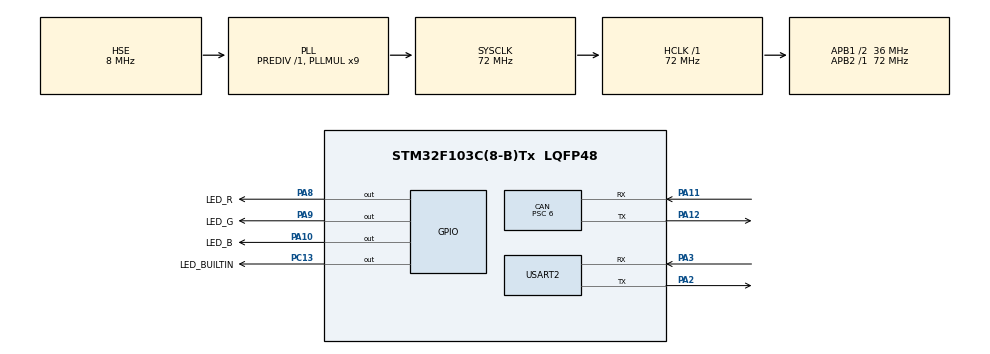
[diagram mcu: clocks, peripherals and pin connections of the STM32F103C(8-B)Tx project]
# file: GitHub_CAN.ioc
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CAN.ABOM=ENABLE
CAN.BS1=CAN_BS1_5TQ
CAN.BS2=CAN_BS2_6TQ
CAN.CalculateBaudRate=500000
CAN.CalculateTimeBit=1999.99
CAN.CalculateTimeQuantum=166.66666666666669
CAN.NART=ENABLE
CAN.Prescaler=6
Dma.Request0=USART2_TX
Dma.Request1=USART2_RX
Dma.USART2_RX.1.Direction=DMA_PERIPH_TO_MEMORY
Dma.USART2_RX.1.Instance=DMA1_Channel6
Dma.USART2_RX.1.MemDataAlignment=DMA_MDATAALIGN_BYTE
Dma.USART2_RX.1.MemInc=DMA_MINC_ENABLE
Dma.USART2_RX.1.Mode=DMA_NORMAL
Dma.USART2_RX.1.PeriphDataAlignment=DMA_PDATAALIGN_BYTE
Dma.USART2_RX.1.PeriphInc=DMA_PINC_DISABLE
Dma.USART2_RX.1.Priority=DMA_PRIORITY_LOW
Dma.USART2_TX.0.Direction=DMA_MEMORY_TO_PERIPH
Dma.USART2_TX.0.Instance=DMA1_Channel7
Dma.USART2_TX.0.MemDataAlignment=DMA_MDATAALIGN_BYTE
Dma.USART2_TX.0.MemInc=DMA_MINC_ENABLE
Dma.USART2_TX.0.Mode=DMA_NORMAL
Dma.USART2_TX.0.PeriphDataAlignment=DMA_PDATAALIGN_BYTE
Dma.USART2_TX.0.PeriphInc=DMA_PINC_DISABLE
Dma.USART2_TX.0.Priority=DMA_PRIORITY_LOW
Mcu.Family=STM32F1
Mcu.Name=STM32F103C(8-B)Tx
Mcu.Package=LQFP48
NVIC.CAN1_RX1_IRQn=true\:0\:0\:false\:false\:true\:true\:true
NVIC.CAN1_SCE_IRQn=true\:0\:0\:false\:false\:true\:true\:true
NVIC.DMA1_Channel6_IRQn=true\:0\:0\:false\:false\:true\:true\:true
NVIC.DMA1_Channel7_IRQn=true\:0\:0\:false\:false\:true\:true\:true
NVIC.PriorityGroup=NVIC_PRIORITYGROUP_4
NVIC.TIM4_IRQn=true\:0\:0\:false\:false\:true\:true\:true
NVIC.TimeBase=TIM4_IRQn
NVIC.TimeBaseIP=TIM4
NVIC.USART2_IRQn=true\:0\:0\:false\:false\:true\:true\:true
NVIC.USB_LP_CAN1_RX0_IRQn=true\:0\:0\:false\:false\:true\:true\:true
PA10.GPIO_Label=LED_B
PA10.PinState=GPIO_PIN_RESET
PA10.Signal=GPIO_Output
PA11.Mode=CAN_Activate
PA11.Signal=CAN_RX
PA12.Mode=CAN_Activate
PA12.Signal=CAN_TX
PA13.Mode=Serial_Wire
PA13.Signal=SYS_JTMS-SWDIO
PA14.Mode=Serial_Wire
PA14.Signal=SYS_JTCK-SWCLK
PA2.Mode=Asynchronous
PA2.Signal=USART2_TX
PA3.Mode=Asynchronous
PA3.Signal=USART2_RX
PA8.GPIO_Label=LED_R
PA8.PinState=GPIO_PIN_RESET
PA8.Signal=GPIO_Output
PA9.GPIO_Label=LED_G
PA9.PinState=GPIO_PIN_RESET
PA9.Signal=GPIO_Output
PC13-TAMPER-RTC.GPIO_Label=LED_BUILTIN
PC13-TAMPER-RTC.PinState=GPIO_PIN_SET
PC13-TAMPER-RTC.Signal=GPIO_Output
PC14-OSC32_IN.Mode=LSE-External-Oscillator
PC14-OSC32_IN.Signal=RCC_OSC32_IN
PC15-OSC32_OUT.Mode=LSE-External-Oscillator
PC15-OSC32_OUT.Signal=RCC_OSC32_OUT
PD0-OSC_IN.Mode=HSE-External-Oscillator
PD0-OSC_IN.Signal=RCC_OSC_IN
PD1-OSC_OUT.Mode=HSE-External-Oscillator
PD1-OSC_OUT.Signal=RCC_OSC_OUT
ProjectManager.HeapSize=0x200
ProjectManager.StackSize=0x400
ProjectManager.TargetToolchain=STM32CubeIDE
RCC.ADCPresc=RCC_ADCPCLK2_DIV6
RCC.AHBFreq_Value=72000000
RCC.APB1CLKDivider=RCC_HCLK_DIV2
RCC.APB1Freq_Value=36000000
RCC.APB1TimFreq_Value=72000000
RCC.APB2Freq_Value=72000000
RCC.APB2TimFreq_Value=72000000
RCC.EnbaleCSS=true
RCC.HCLKFreq_Value=72000000
RCC.PLLMUL=RCC_PLL_MUL9
RCC.PLLSourceVirtual=RCC_PLLSOURCE_HSE
RCC.SYSCLKFreq_VALUE=72000000
RCC.SYSCLKSource=RCC_SYSCLKSOURCE_PLLCLK
RCC.USBFreq_Value=48000000
RCC.USBPrescaler=RCC_USBCLKSOURCE_PLL_DIV1_5
USART2.VirtualMode=VM_ASYNC
VP_CRC_VS_CRC.Mode=CRC_Activate
VP_SYS_VS_tim4.Mode=TIM4
board=cubemx_can

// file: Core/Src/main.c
/* USER CODE BEGIN Header */
/**
 ******************************************************************************
 * @file           : main.c
 * @brief          : Main program body
 ******************************************************************************
 * @attention
 *
 * <h2><center>&copy; Copyright (c) 2021 STMicroelectronics.
 * All rights reserved.</center></h2>
 *
 * This software component is licensed by ST under BSD 3-Clause license,
 * the "License"; You may not use this file except in compliance with the
 * License. You may obtain a copy of the License at:
 *                        opensource.org/licenses/BSD-3-Clause
 *
 ******************************************************************************
 */
/* USER CODE END Header */
#include "main.h"

CAN_HandleTypeDef hcan;

CRC_HandleTypeDef hcrc;

UART_HandleTypeDef huart2;
DMA_HandleTypeDef hdma_usart2_tx;
DMA_HandleTypeDef hdma_usart2_rx;

/* USER CODE BEGIN PV */
/* Private variables ---------------------------------------------------------*/

/* USER CODE END PV */

void SystemClock_Config(void);
static void MX_GPIO_Init(void);
static void MX_DMA_Init(void);
static void MX_CAN_Init(void);
static void MX_CRC_Init(void);
static void MX_USART2_UART_Init(void);
/* USER CODE BEGIN PFP */
/* Private function prototypes -----------------------------------------------*/

/* USER CODE END PFP */

int main(void)
{
	/* USER CODE BEGIN 1 */
	uint8_t tx_data[8] = {0};
	uint32_t tx_mailbox_number;
	/* USER CODE END 1 */

	/* MCU Configuration--------------------------------------------------------*/

	/* Reset of all peripherals, Initializes the Flash interface and the Systick. */
	HAL_Init();

	/* Configure the system clock */
	SystemClock_Config();

	/* Initialize all configured peripherals */
	MX_GPIO_Init();
	MX_DMA_Init();
	MX_CAN_Init();
	MX_CRC_Init();
	MX_USART2_UART_Init();
	/* USER CODE BEGIN 2 */
	/* start can */
	HAL_CAN_Start(&hcan);

	/* setup transmit header */
	CAN_TxHeaderTypeDef tx_header;
	tx_header.StdId = 0x545U;
	tx_header.RTR = CAN_RTR_DATA;
	tx_header.IDE = CAN_ID_STD;
	tx_header.DLC = 5U;
	tx_header.TransmitGlobalTime = DISABLE;

	/* USER CODE END 2 */

	/* Infinite loop */
	while (1)
	{

		/* USER CODE BEGIN 3 */
		tx_data[0] = !tx_data[0];
		HAL_CAN_AddTxMessage(&hcan, &tx_header, tx_data, &tx_mailbox_number);
		HAL_Delay(2000U);
	}
	/* USER CODE END 3 */
}

void SystemClock_Config(void)
{
	RCC_OscInitTypeDef RCC_OscInitStruct = {0};
	RCC_ClkInitTypeDef RCC_ClkInitStruct = {0};

	/** Initializes the RCC Oscillators according to the specified parameters
	 * in the RCC_OscInitTypeDef structure.
	 */
	RCC_OscInitStruct.OscillatorType = RCC_OSCILLATORTYPE_HSE;
	RCC_OscInitStruct.HSEState = RCC_HSE_ON;
	RCC_OscInitStruct.HSEPredivValue = RCC_HSE_PREDIV_DIV1;
	RCC_OscInitStruct.HSIState = RCC_HSI_ON;
	RCC_OscInitStruct.PLL.PLLState = RCC_PLL_ON;
	RCC_OscInitStruct.PLL.PLLSource = RCC_PLLSOURCE_HSE;
	RCC_OscInitStruct.PLL.PLLMUL = RCC_PLL_MUL9;
	if (HAL_RCC_OscConfig(&RCC_OscInitStruct) != HAL_OK)
	{
		Error_Handler();
	}
	/** Initializes the CPU, AHB and APB buses clocks
	 */
	RCC_ClkInitStruct.ClockType = RCC_CLOCKTYPE_HCLK|RCC_CLOCKTYPE_SYSCLK
			|RCC_CLOCKTYPE_PCLK1|RCC_CLOCKTYPE_PCLK2;
	RCC_ClkInitStruct.SYSCLKSource = RCC_SYSCLKSOURCE_PLLCLK;
	RCC_ClkInitStruct.AHBCLKDivider = RCC_SYSCLK_DIV1;
	RCC_ClkInitStruct.APB1CLKDivider = RCC_HCLK_DIV2;
	RCC_ClkInitStruct.APB2CLKDivider = RCC_HCLK_DIV1;

	if (HAL_RCC_ClockConfig(&RCC_ClkInitStruct, FLASH_LATENCY_2) != HAL_OK)
	{
		Error_Handler();
	}
	/** Enables the Clock Security System
	 */
	HAL_RCC_EnableCSS();
}

static void MX_CAN_Init(void)
{

	hcan.Instance = CAN1;
	hcan.Init.Prescaler = 6;
	hcan.Init.Mode = CAN_MODE_NORMAL;
	hcan.Init.SyncJumpWidth = CAN_SJW_1TQ;
	hcan.Init.TimeSeg1 = CAN_BS1_5TQ;
	hcan.Init.TimeSeg2 = CAN_BS2_6TQ;
	hcan.Init.TimeTriggeredMode = DISABLE;
	hcan.Init.AutoBusOff = ENABLE;
	hcan.Init.AutoWakeUp = DISABLE;
	hcan.Init.AutoRetransmission = ENABLE;
	hcan.Init.ReceiveFifoLocked = DISABLE;
	hcan.Init.TransmitFifoPriority = DISABLE;
	if (HAL_CAN_Init(&hcan) != HAL_OK)
	{
		Error_Handler();
	}

}

static void MX_CRC_Init(void)
{

	hcrc.Instance = CRC;
	if (HAL_CRC_Init(&hcrc) != HAL_OK)
	{
		Error_Handler();
	}

}

static void MX_USART2_UART_Init(void)
{

	huart2.Instance = USART2;
	huart2.Init.BaudRate = 115200;
	huart2.Init.WordLength = UART_WORDLENGTH_8B;
	huart2.Init.StopBits = UART_STOPBITS_1;
	huart2.Init.Parity = UART_PARITY_NONE;
	huart2.Init.Mode = UART_MODE_TX_RX;
	huart2.Init.HwFlowCtl = UART_HWCONTROL_NONE;
	huart2.Init.OverSampling = UART_OVERSAMPLING_16;
	if (HAL_UART_Init(&huart2) != HAL_OK)
	{
		Error_Handler();
	}

}

static void MX_DMA_Init(void)
{

	/* DMA controller clock enable */
	__HAL_RCC_DMA1_CLK_ENABLE();

	/* DMA interrupt init */
	/* DMA1_Channel6_IRQn interrupt configuration */
	HAL_NVIC_SetPriority(DMA1_Channel6_IRQn, 0, 0);
	HAL_NVIC_EnableIRQ(DMA1_Channel6_IRQn);
	/* DMA1_Channel7_IRQn interrupt configuration */
	HAL_NVIC_SetPriority(DMA1_Channel7_IRQn, 0, 0);
	HAL_NVIC_EnableIRQ(DMA1_Channel7_IRQn);

}

static void MX_GPIO_Init(void)
{
	GPIO_InitTypeDef GPIO_InitStruct = {0};

	/* GPIO Ports Clock Enable */
	__HAL_RCC_GPIOC_CLK_ENABLE();
	__HAL_RCC_GPIOD_CLK_ENABLE();
	__HAL_RCC_GPIOA_CLK_ENABLE();

	/*Configure GPIO pin Output Level */
	HAL_GPIO_WritePin(LED_BUILTIN_GPIO_Port, LED_BUILTIN_Pin, GPIO_PIN_SET);

	/*Configure GPIO pin Output Level */
	HAL_GPIO_WritePin(GPIOA, LED_R_Pin|LED_G_Pin|LED_B_Pin, GPIO_PIN_RESET);

	/*Configure GPIO pin : LED_BUILTIN_Pin */
	GPIO_InitStruct.Pin = LED_BUILTIN_Pin;
	GPIO_InitStruct.Mode = GPIO_MODE_OUTPUT_PP;
	GPIO_InitStruct.Pull = GPIO_NOPULL;
	GPIO_InitStruct.Speed = GPIO_SPEED_FREQ_LOW;
	HAL_GPIO_Init(LED_BUILTIN_GPIO_Port, &GPIO_InitStruct);

	/*Configure GPIO pins : LED_R_Pin LED_G_Pin LED_B_Pin */
	GPIO_InitStruct.Pin = LED_R_Pin|LED_G_Pin|LED_B_Pin;
	GPIO_InitStruct.Mode = GPIO_MODE_OUTPUT_PP;
	GPIO_InitStruct.Pull = GPIO_NOPULL;
	GPIO_InitStruct.Speed = GPIO_SPEED_FREQ_LOW;
	HAL_GPIO_Init(GPIOA, &GPIO_InitStruct);

}

void HAL_TIM_PeriodElapsedCallback(TIM_HandleTypeDef *htim)
{
	if (htim->Instance == TIM4) {
		HAL_IncTick();
	}
}

void Error_Handler(void)
{
	while(1)
	{
	}
}

/************************ (C) COPYRIGHT STMicroelectronics *****END OF FILE****/
